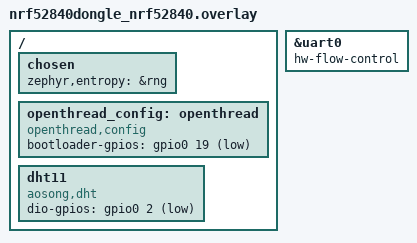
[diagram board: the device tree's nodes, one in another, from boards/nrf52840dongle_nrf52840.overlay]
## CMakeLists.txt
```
#
# Copyright (c) 2020 Nordic Semiconductor ASA
#
# SPDX-License-Identifier: LicenseRef-Nordic-5-Clause
#
cmake_minimum_required(VERSION 3.20.0)

find_package(Zephyr REQUIRED HINTS $ENV{ZEPHYR_BASE})

project(cli)

# NORDIC SDK APP START
target_sources(app PRIVATE src/main.c)
# NORDIC SDK APP END

target_sources_ifdef(CONFIG_CLI_SAMPLE_MULTIPROTOCOL app PRIVATE src/ble.c)
target_sources_ifdef(CONFIG_CLI_SAMPLE_LOW_POWER app PRIVATE src/low_power.c)


if (CONFIG_CLI_SAMPLE_MULTIPROTOCOL AND CONFIG_OPENTHREAD_BLE_TCAT)
        message( FATAL_ERROR "Multiprotocol support and TCAT functionality are not compatible." )
endif()
```

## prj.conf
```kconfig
#
# Copyright (c) 2020 Nordic Semiconductor
#
# SPDX-License-Identifier: LicenseRef-Nordic-5-Clause
#

# Network shell
CONFIG_SHELL=y
CONFIG_OPENTHREAD_SHELL=y
CONFIG_SHELL_ARGC_MAX=26
CONFIG_SHELL_CMD_BUFF_SIZE=416

# Increase Settings storage size
CONFIG_PM_PARTITION_SIZE_SETTINGS_STORAGE=0x8000

# Enable OpenThread features set
CONFIG_OPENTHREAD_NORDIC_LIBRARY_MASTER=y

CONFIG_NET_L2_OPENTHREAD=y

# Generic networking options
CONFIG_NETWORKING=y

CONFIG_GPIO_SHELL=y

CONFIG_OPENTHREAD_UDP_FORWARD=y

CONFIG_SENSOR=y
CONFIG_DHT=y

# Enable float printing in newlib
CONFIG_NEWLIB_LIBC=y
CONFIG_NEWLIB_LIBC_FLOAT_PRINTF=y

# Need float format support
CONFIG_REQUIRES_FULL_LIBC=y
CONFIG_REQUIRES_FLOAT_PRINTF=y
CONFIG_CBPRINTF_FP_SUPPORT=y

# UART configuration
CONFIG_SERIAL=y
CONFIG_UART_INTERRUPT_DRIVEN=y
CONFIG_USB_DEVICE_STACK=y
CONFIG_USB_CDC_ACM=y

# Enable Zephyr threading (optional)
CONFIG_THREAD_MONITOR=y

CONFIG_MAIN_STACK_SIZE=4096
CONFIG_SYSTEM_WORKQUEUE_STACK_SIZE=4096

# Enable Bluetooth
CONFIG_BT=y
CONFIG_BT_PERIPHERAL=y
CONFIG_BT_DEVICE_NAME="Thread+BLE Device"
CONFIG_BT_GATT_SERVICE_CHANGED=y

# Enable multiprotocol (for BLE + Thread)
CONFIG_MPSL=y
CONFIG_CLI_SAMPLE_MULTIPROTOCOL=y
```

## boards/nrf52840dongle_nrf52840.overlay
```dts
/* Copyright (c) 2024 Nordic Semiconductor ASA
 *
 * SPDX-License-Identifier: LicenseRef-Nordic-5-Clause
 */

&uart0 {
	status = "okay";
	hw-flow-control;
};

/ {
	/*
	* In some default configurations within the nRF Connect SDK,
	* e.g. on nRF52840, the chosen zephyr,entropy node is &cryptocell.
	* This devicetree overlay ensures that default is overridden wherever it
	* is set, as this application uses the RNG node for entropy exclusively.
	*/
	chosen {
		zephyr,entropy = &rng;
	};

	/*
	 * nRF52840 dongle has pin P0.19 connected to reset. By setting it
	 * in `GPIO_OUTPUT_ACTIVE` mode, reset is pulled to GND,
	 * which results in device rebooting without skipping the bootloader.
	 * openthread_config node enables doing so using `ot reset bootloader` command.
	 */
	openthread_config: openthread {
		compatible = "openthread,config";
		bootloader-gpios = <&gpio0 19 GPIO_ACTIVE_LOW>;
	};
};

/ {
	dht11 {
		compatible = "aosong,dht";
		status = "okay";
		dio-gpios = <&gpio0 2 (GPIO_PULL_UP | GPIO_ACTIVE_LOW)>;
		
	};
};
```

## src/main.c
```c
/*
 * Copyright (c) 2020 Nordic Semiconductor ASA
 *
 * SPDX-License-Identifier: LicenseRef-Nordic-5-Clause
 */

 #include <zephyr/kernel.h>
 #include <stdio.h>
 #include <stdlib.h>
 #include <zephyr/logging/log.h>
 #include <openthread/platform/radio.h>
 #include <openthread/thread.h>
 #include <openthread/udp.h>
 #include <zephyr/drivers/uart.h>
 #include <zephyr/usb/usb_device.h>
 #include <openthread/instance.h>
 #include "ble.h"
 
 LOG_MODULE_REGISTER(cli_sample, CONFIG_OT_COMMAND_LINE_INTERFACE_LOG_LEVEL);
 
 static const char UDP_DEST_ADDR[] = "fd40:3477:6aa4:1:9da4:1bf2:475e:efe9"; // OTBR IPv6 Address
 static const uint16_t UDP_PORT = 1234;  // Choose a suitable UDP port
 
 static char udpPayload[50];  // Buffer for UDP payload
 static otInstance *instance;
 static otUdpSocket udpSocket;
 
 static const struct device *uart_dev = DEVICE_DT_GET(DT_CHOSEN(zephyr_console));
 
 void udpSend(void) {
	 otError error;
	 otMessage *message;
	 otMessageInfo messageInfo;
 
	 message = otUdpNewMessage(instance, NULL);
	 if (message == NULL) {
		 LOG_ERR("Failed to allocate message");
		 return;
	 }
 
	 error = otMessageAppend(message, udpPayload, strlen(udpPayload));
	 if (error != OT_ERROR_NONE) {
		 LOG_ERR("Failed to append message: %d", error);
		 otMessageFree(message);
		 return;
	 }
 
	 memset(&messageInfo, 0, sizeof(messageInfo));
	 otIp6AddressFromString(UDP_DEST_ADDR, &messageInfo.mPeerAddr);
	 messageInfo.mPeerPort = UDP_PORT;
 
	 error = otUdpSend(instance, &udpSocket, message, &messageInfo);
	 if (error != OT_ERROR_NONE) {
		 LOG_ERR("Failed to send UDP message: %d", error);
		 otMessageFree(message);
	 } else {
		 LOG_INF("UDP message sent: %s", udpPayload);
		 memset(udpPayload, 0, sizeof(udpPayload));  // Clear buffer after sending
	 }
 }
 
 void uart_cb(const struct device *dev, void *user_data) {
	 static int idx = 0;
	 uint8_t c;
 
	 while (uart_irq_update(dev) && uart_irq_rx_ready(dev)) {
		 uart_fifo_read(dev, &c, 1);
		 if (c == '\n' || idx >= sizeof(udpPayload) - 1) {
			 udpPayload[idx] = '\0';
			 LOG_INF("Received UART data: %s", udpPayload);
 
			 // Check if the message is "FAN"
			 if (strcmp(udpPayload, "FAN") == 0) {
				 LOG_INF("Triggering notification for FAN");
				 trigger_notification("Triggered");
			 } else {
				 udpSend();
			 }
			 idx = 0;
		 } else {
			 udpPayload[idx++] = c;
		 }
	 }
 }
 
 void main(void) {
	 LOG_INF("Thread UDP Sender + BLE starting...");
 
	 /* Initialize BLE (from ble.c/ble.h) */
	 // COMMENT THESE 2 LINES OUT FOR THOSE NOT USING BLE
	 ble_enable();
	 LOG_INF("BLE initialized and advertising...");
 
	 if (!device_is_ready(uart_dev)) {
		 LOG_ERR("UART device not ready");
		 return;
	 }
	 
	 // Enable UART (COMMENT THESE 2 LINES OUT WHEN SETTING UP THREAD, THEN REFLASH UNCOMMENTED AFTER SET UP)
	//  uart_irq_callback_user_data_set(uart_dev, uart_cb, NULL);
	//  uart_irq_rx_enable(uart_dev);
 
	 instance = otInstanceInitSingle();
	 if (instance == NULL) {
		 LOG_ERR("Failed to initialize OpenThread instance");
		 return;
	 }
 
	 otError error = otIp6SetEnabled(instance, true);
	 if (error != OT_ERROR_NONE) {
		 LOG_ERR("Failed to enable IPv6: %d", error);
		 return;
	 }
 
	 error = otThreadSetEnabled(instance, true);
	 if (error != OT_ERROR_NONE) {
		 LOG_ERR("Failed to enable Thread: %d", error);
		 return;
	 }
 
	 memset(&udpSocket, 0, sizeof(udpSocket));
	 error = otUdpOpen(instance, &udpSocket, NULL, NULL);
	 if (error != OT_ERROR_NONE) {
		 LOG_ERR("Failed to open UDP socket: %d", error);
		 return;
	 }
 
	 LOG_INF("Waiting for UART data...");
	 while (1) {
		 k_sleep(K_MSEC(1000));
	 }
 }
 
```

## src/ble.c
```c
/*
 * Copyright (c) 2020 Nordic Semiconductor ASA
 *
 * SPDX-License-Identifier: LicenseRef-Nordic-5-Clause
 */

 #include <zephyr/kernel.h>
 #include <zephyr/bluetooth/bluetooth.h>
 #include <zephyr/bluetooth/gatt.h>
 #include <string.h>
 #include <stdio.h>
 #include "ble.h"
 
 /* Fallback in case CONFIG_BT_DEVICE_NAME isn't defined */
 #ifndef CONFIG_BT_DEVICE_NAME
 #define CONFIG_BT_DEVICE_NAME "Thread+BLE Device"
 #endif
 
 #define DEVICE_NAME CONFIG_BT_DEVICE_NAME
 #define DEVICE_NAME_LEN (sizeof(DEVICE_NAME) - 1)
 
 #define ADV_INT_MIN 0x01e0 /* 300 ms */
 #define ADV_INT_MAX 0x0260 /* 380 ms */
 
 /* Advertising Data */
 static const struct bt_data ad[] = {
	 BT_DATA_BYTES(BT_DATA_FLAGS, (BT_LE_AD_GENERAL | BT_LE_AD_NO_BREDR)),
	 BT_DATA(BT_DATA_NAME_COMPLETE, DEVICE_NAME, DEVICE_NAME_LEN),
 };
 
 /* Connection callbacks */
 static void connected_cb(struct bt_conn *conn, uint8_t err)
 {
	 if (err) {
		 printk("Connection failed (err %u)\n", err);
	 } else {
		 printk("Central connected.\n");
	 }
 }
 
 static void disconnected_cb(struct bt_conn *conn, uint8_t reason)
 {
	 printk("Central disconnected (reason 0x%02x)\n", reason);
 }
 
 static struct bt_conn_cb conn_callbacks = {
	 .connected = connected_cb,
	 .disconnected = disconnected_cb,
 };
 
 /* Custom GATT Service and Characteristic UUIDs */
 static struct bt_uuid_128 custom_service_uuid = BT_UUID_INIT_128(
	 0x12, 0x34, 0x56, 0x78,
	 0x12, 0x34, 0x56, 0x78,
	 0x12, 0x34, 0x56, 0x78,
	 0x12, 0x34, 0x56, 0x78);
 
 static struct bt_uuid_128 custom_char_uuid = BT_UUID_INIT_128(
	 0xab, 0xcd, 0xef, 0x01,
	 0xab, 0xcd, 0xef, 0x01,
	 0xab, 0xcd, 0xef, 0x01,
	 0xab, 0xcd, 0xef, 0x01);
 
 /* Storage for the custom characteristic value */
 static uint8_t custom_char_value[20] = "Hello M5Stick!";
 
 /* Read callback for the custom characteristic */
 static ssize_t read_custom_char(struct bt_conn *conn,
				 const struct bt_gatt_attr *attr,
				 void *buf, uint16_t len, uint16_t offset)
 {
	 const char *value = attr->user_data;
	 return bt_gatt_attr_read(conn, attr, buf, len, offset, value, strlen(value));
 }
 
 /* Write callback for the custom characteristic */
 static ssize_t write_custom_char(struct bt_conn *conn,
				  const struct bt_gatt_attr *attr,
				  const void *buf, uint16_t len,
				  uint16_t offset, uint8_t flags)
 {
	 char *value = attr->user_data;
 
	 if (offset + len > sizeof(custom_char_value)) {
		 return BT_GATT_ERR(BT_ATT_ERR_INVALID_OFFSET);
	 }
 
	 memcpy(value + offset, buf, len);
	 /* Add a null terminator if possible */
	 if (offset + len < sizeof(custom_char_value)) {
		 value[offset + len] = '\0';
	 }
 
	 printk("Custom Characteristic updated: %s\n", value);
	 return len;
 }
 
 /* Define the custom GATT service with one read/write/notify characteristic */
 BT_GATT_SERVICE_DEFINE(custom_service,
    BT_GATT_PRIMARY_SERVICE(&custom_service_uuid),
    BT_GATT_CHARACTERISTIC(&custom_char_uuid.uuid,
                           BT_GATT_CHRC_READ | BT_GATT_CHRC_WRITE | BT_GATT_CHRC_NOTIFY,
                           BT_GATT_PERM_READ | BT_GATT_PERM_WRITE,
                           read_custom_char, write_custom_char, custom_char_value),
    BT_GATT_CCC(NULL, BT_GATT_PERM_READ | BT_GATT_PERM_WRITE),
);

 /*
  * trigger_notification() sends a notification with the provided message.
  * Adjust the index if your service structure is different.
  */
 void trigger_notification(const char *msg)
 {
	 /* 
	  * BT_GATT_SERVICE_DEFINE creates an array named 'custom_service' containing
	  * the attributes for the service. The characteristic value attribute is usually
	  * at index 2 (primary service is index 0, characteristic declaration index 1).
	  */
	 struct bt_gatt_attr *chrc_attr = (struct bt_gatt_attr *)&custom_service.attrs[2];
	 printk("trigger_notification() called with msg: %s\n", msg);
	 bt_gatt_notify(NULL, chrc_attr, msg, strlen(msg));
	 printk("bt_gatt_notify() complete.\n");
 }
 
 /* BLE initialization and advertising */
 void ble_enable(void)
 {
	 const struct bt_le_adv_param *adv_param = BT_LE_ADV_PARAM(
		 BT_LE_ADV_OPT_CONNECTABLE,
		 ADV_INT_MIN,
		 ADV_INT_MAX,
		 NULL
	 );
 
	 int err = bt_enable(NULL);
	 if (err) {
		 printk("Bluetooth init failed (err %d)\n", err);
		 return;
	 }
 
	 bt_conn_cb_register(&conn_callbacks);
 
	 err = bt_le_adv_start(adv_param, ad, ARRAY_SIZE(ad), NULL, 0);
	 if (err) {
		 printk("Advertising failed to start (err %d)\n", err);
		 return;
	 }
 
	 printk("BLE advertising started. Custom GATT service initialized.\n");
 }
 
//-----------------------Below original code(initial code) from the ble.c-------------------------------//

// /*
//  * Copyright (c) 2020 Nordic Semiconductor ASA
//  *
//  * SPDX-License-Identifier: LicenseRef-Nordic-5-Clause
//  */

// #include <zephyr/kernel.h>
// #include <zephyr/bluetooth/gatt.h>

// #include "ble.h"

// #define DEVICE_NAME CONFIG_BT_DEVICE_NAME
// #define DEVICE_NAME_LEN (sizeof(DEVICE_NAME) - 1)

// #define ADV_INT_MIN 0x01e0 /* 300 ms */
// #define ADV_INT_MAX 0x0260 /* 380 ms */

// static const struct bt_data ad[] = {
// 	BT_DATA_BYTES(BT_DATA_FLAGS, (BT_LE_AD_GENERAL | BT_LE_AD_NO_BREDR)),
// 	BT_DATA(BT_DATA_NAME_COMPLETE, DEVICE_NAME, DEVICE_NAME_LEN),
// };

// static struct bt_conn_cb conn_callbacks;

// void ble_enable(void)
// {
// 	const struct bt_le_adv_param *adv_param = BT_LE_ADV_PARAM(
// 		BT_LE_ADV_OPT_CONNECTABLE | BT_LE_ADV_OPT_ONE_TIME, ADV_INT_MIN, ADV_INT_MAX, NULL);

// 	bt_enable(NULL);
// 	bt_conn_cb_register(&conn_callbacks);
// 	bt_le_adv_start(adv_param, ad, ARRAY_SIZE(ad), NULL, 0);
// }
```

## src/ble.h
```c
/**
 * @file
 * @defgroup ble Bluetooth LE API
 * @{
 */

/*
 * Copyright (c) 2020 Nordic Semiconductor ASA
 *
 * SPDX-License-Identifier: LicenseRef-Nordic-5-Clause
 */

#ifndef __BLE_H__
#define __BLE_H__

/** @brief Initialize BLE.
 */
void ble_enable(void);
void trigger_notification(const char *msg);

#endif

/**
 * @}
 */
```

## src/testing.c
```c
// /*
//  * Copyright (c) 2020 Nordic Semiconductor ASA
//  *
//  * SPDX-License-Identifier: LicenseRef-Nordic-5-Clause
//  */

//  #include <zephyr/kernel.h>
//  #include <stdio.h>
//  #include <zephyr/logging/log.h>
//  #include <openthread/platform/radio.h>
//  #include <openthread/thread.h>
//  #include <openthread/udp.h>
//  #include <zephyr/drivers/uart.h>
//  #include <zephyr/usb/usb_device.h>
//  #include <zephyr/drivers/sensor.h> 
 
//  static const char UDP_DEST_ADDR[] = "fd34:3efd:9d7:1:b089:a484:57bd:518f";  // IPv6 Address of OTBR
//  static const uint16_t UDP_PORT = 1234;  // Choose a suitable UDP port
 
//  static char udpPayload[70];  // Payload to send over UDP
//  static otInstance *instance;
//  static otUdpSocket udpSocket;
//  LOG_MODULE_REGISTER(cli_sample, CONFIG_OT_COMMAND_LINE_INTERFACE_LOG_LEVEL);
 
//  /* Function to get the current timestamp as a formatted string */
//  static const char *now_str(void)
//  {
//      static char buf[20]; /* HH:MM:SS.MMM */
//      uint32_t now = k_uptime_get_32();
//      unsigned int ms = now % MSEC_PER_SEC;
//      unsigned int s;
//      unsigned int min;
//      unsigned int h;
 
//      now /= MSEC_PER_SEC;
//      s = now % 60U;
//      now /= 60U;
//      min = now % 60U;
//      now /= 60U;
//      h = now;
 
//      snprintf(buf, sizeof(buf), "%02u:%02u:%02u.%03u", h, min, s, ms);
//      return buf;
//  }
 
//  /* Function to read temperature and humidity from DHT-11 */
//  void get_sensor_data(char *buffer, size_t buffer_size)
//  {
//      const struct device *const dht22 = DEVICE_DT_GET_ONE(aosong_dht);
     
//      if (!device_is_ready(dht22)) {
//          LOG_ERR("DHT Sensor %s is NOT ready!", dht22->name);
//          snprintf(buffer, buffer_size, "[%s] Sensor Error", now_str());
//          return;
//      }
 
//      int rc = sensor_sample_fetch(dht22);
//      if (rc != 0) {
//          LOG_ERR("Sensor fetch failed: %d\n", rc);
//          snprintf(buffer, buffer_size, "[%s] Sensor Fetch Error", now_str());
//          return;
//      }
 
//      struct sensor_value temperature;
//      struct sensor_value humidity;
 
//      rc = sensor_channel_get(dht22, SENSOR_CHAN_AMBIENT_TEMP, &temperature);
//      if (rc == 0) {
//          rc = sensor_channel_get(dht22, SENSOR_CHAN_HUMIDITY, &humidity);
//      }
 
//      if (rc != 0) {
//          LOG_ERR("Sensor read failed: %d", rc);
//          snprintf(buffer, buffer_size, "[%s] Sensor Read Error", now_str());
//          return;
//      }
 
//      snprintf(buffer, buffer_size, "[%s] Temp: %.1f°C, Humid: %.1f%% RH\n",
//               now_str(),
//               sensor_value_to_double(&temperature),
//               sensor_value_to_double(&humidity));
//  }
 
//  /* Function to send UDP packet with sensor data */
//  void udpSend(otInstance *instance)
//  {
//      otError error;
//      otMessage *message;
//      otMessageInfo messageInfo;
 
//      get_sensor_data(udpPayload, sizeof(udpPayload));  // Get sensor data
 
//      // Create a new message
//      message = otUdpNewMessage(instance, NULL);
//      if (message == NULL)
//      {
//          LOG_ERR("Failed to allocate message");
//          return;
//      }
 
//      // Append the payload to the message
//      error = otMessageAppend(message, udpPayload, strlen(udpPayload));
//      if (error != OT_ERROR_NONE)
//      {
//          LOG_ERR("Failed to append message: %d", error);
//          otMessageFree(message);
//          return;
//      }
 
//      // Set the message info
//      memset(&messageInfo, 0, sizeof(messageInfo));
//      otIp6AddressFromString(UDP_DEST_ADDR, &messageInfo.mPeerAddr);
//      messageInfo.mPeerPort = UDP_PORT;
 
//      // Send the message
//      error = otUdpSend(instance, &udpSocket, message, &messageInfo);
//      if (error != OT_ERROR_NONE)
//      {
//          LOG_ERR("Failed to send UDP message: %d", error);
//          otMessageFree(message);
//      }
//  }
 
//  int main(void)
//  {
//      // Initialize OpenThread instance
//      instance = otInstanceInitSingle();
//      if (instance == NULL)
//      {
//          LOG_ERR("Failed to initialize OpenThread instance");
//          return -1;
//      }
 
//      // Bring up the IPv6 interface
//      otError error = otIp6SetEnabled(instance, true);
//      if (error != OT_ERROR_NONE)
//      {
//          LOG_ERR("Failed to bring up IPv6 interface: %d", error);
//          return -1;
//      }
 
//      // Start the Thread network
//      error = otThreadSetEnabled(instance, true);
//      if (error != OT_ERROR_NONE)
//      {
//          LOG_ERR("Failed to start Thread network: %d", error);
//          return -1;
//      }
 
//      // Initialize the UDP socket
//      memset(&udpSocket, 0, sizeof(udpSocket));
//      otUdpOpen(instance, &udpSocket, NULL, NULL);
 
//      while (1)
//      {
//          udpSend(instance);
//          k_sleep(K_SECONDS(2)); // Send a message every 2 seconds
//      }
 
//      return 0;
//  }
 
```
